VERSION ""

NS_ :

BS_:

BU_: IBST ESP EPAS EPAS3P APS APP DAS

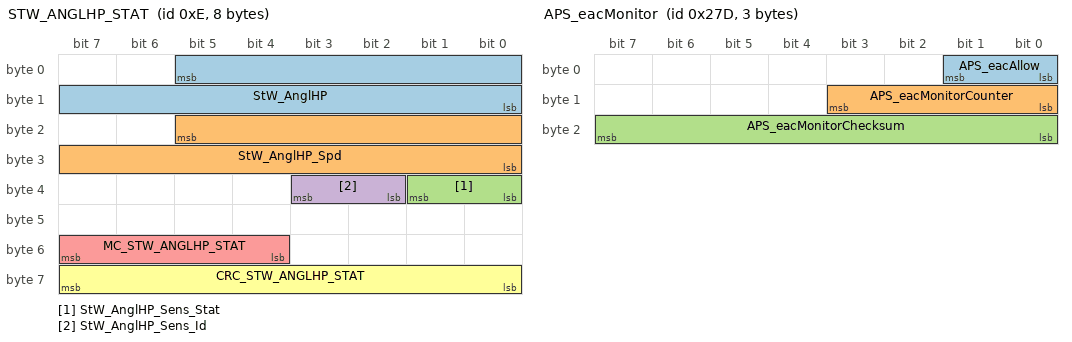
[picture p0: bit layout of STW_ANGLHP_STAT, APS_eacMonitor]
BO_ 14 STW_ANGLHP_STAT: 8 APS
  SG_ StW_AnglHP : 5|14@0+ (0.1,-819.2) [-819.2|819] "deg" EPAS3P
  SG_ StW_AnglHP_Spd : 21|14@0+ (0.5,-4096) [-4096|4095.5] "deg/s" EPAS3P
  SG_ StW_AnglHP_Sens_Stat : 33|2@0+ (1,0) [0|0] "" EPAS3P
  SG_ StW_AnglHP_Sens_Id : 35|2@0+ (1,0) [0|0] "" EPAS3P
  SG_ MC_STW_ANGLHP_STAT : 55|4@0+ (1,0) [0|15] "" EPAS3P
  SG_ CRC_STW_ANGLHP_STAT : 63|8@0+ (1,0) [0|0] "" EPAS3P

BO_ 637 APS_eacMonitor: 3 APS
  SG_ APS_eacAllow : 0|2@1+ (1,0) [0|0] "" EPAS3P
  SG_ APS_eacMonitorCounter : 8|4@1+ (1,0) [0|0] "" EPAS3P
  SG_ APS_eacMonitorChecksum : 16|8@1+ (1,0) [0|0] "" EPAS3P

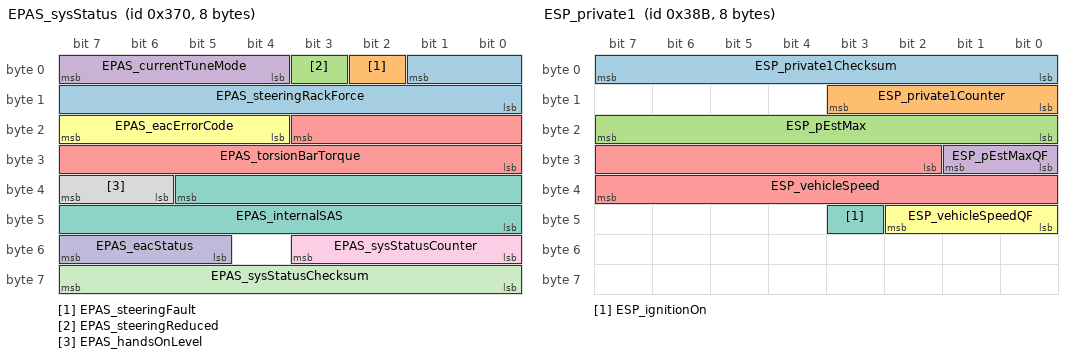
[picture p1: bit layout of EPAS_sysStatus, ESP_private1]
BO_ 880 EPAS_sysStatus: 8 EPAS
  SG_ EPAS_steeringRackForce : 1|10@0+ (50,-25575) [-25575|25575] "N" Vector__XXX
  SG_ EPAS_steeringFault : 2|1@0+ (1,0) [0|1] "" APS,APP
  SG_ EPAS_steeringReduced : 3|1@0+ (1,0) [0|1] "" APS,APP
  SG_ EPAS_currentTuneMode : 7|4@0+ (1,0) [0|0] "" APS,APP
  SG_ EPAS_torsionBarTorque : 19|12@0+ (0.01,-20.5) [-20.5|20.45] "Nm" APS,APP
  SG_ EPAS_eacErrorCode : 23|4@0+ (1,0) [0|15] "" APS,APP
  SG_ EPAS_internalSAS : 37|14@0+ (0.1,-819.2) [-819.2|819] "deg" APS,APP
  SG_ EPAS_handsOnLevel : 39|2@0+ (1,0) [0|3] "" APS,APP
  SG_ EPAS_sysStatusCounter : 51|4@0+ (1,0) [0|15] "" APS,APP
  SG_ EPAS_eacStatus : 55|3@0+ (1,0) [0|7] "" APS,APP
  SG_ EPAS_sysStatusChecksum : 63|8@0+ (1,0) [0|255] "" APS,APP

BO_ 907 ESP_private1: 8 ESP
  SG_ ESP_private1Checksum : 0|8@1+ (1,0) [0|255] "" IBST,EPAS
  SG_ ESP_private1Counter : 8|4@1+ (1,0) [0|15] "" IBST,EPAS
  SG_ ESP_pEstMax : 16|8@1+ (1,0) [0|250] "bar" IBST
  SG_ ESP_pEstMaxQF : 24|2@1+ (1,0) [0|2] "" IBST
  SG_ ESP_vehicleSpeed : 26|14@1+ (0.05625,0) [0|921.54375] "km/h" IBST,EPAS
  SG_ ESP_vehicleSpeedQF : 40|3@1+ (1,0) [0|6] "" IBST,EPAS
  SG_ ESP_ignitionOn : 43|1@1+ (1,0) [0|1] "" IBST

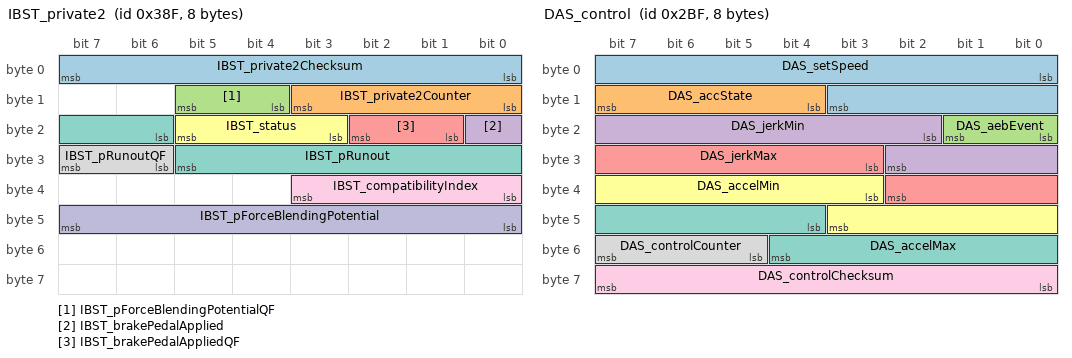
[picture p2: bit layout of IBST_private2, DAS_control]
BO_ 911 IBST_private2: 8 IBST
  SG_ IBST_private2Checksum : 0|8@1+ (1,0) [0|255] "" ESP
  SG_ IBST_private2Counter : 8|4@1+ (1,0) [0|15] "" ESP
  SG_ IBST_pForceBlendingPotentialQF : 12|2@1+ (1,0) [0|2] "" ESP
  SG_ IBST_brakePedalApplied : 16|1@1+ (1,0) [0|1] "1" ESP
  SG_ IBST_brakePedalAppliedQF : 17|2@1+ (1,0) [0|3] "" ESP
  SG_ IBST_status : 19|3@1+ (1,0) [0|7] "1" ESP
  SG_ IBST_pRunout : 22|8@1+ (1,0) [0|250] "bar" ESP
  SG_ IBST_pRunoutQF : 30|2@1+ (1,0) [0|3] "" ESP
  SG_ IBST_compatibilityIndex : 32|4@1+ (1,0) [0|15] "" ESP
  SG_ IBST_pForceBlendingPotential : 40|8@1+ (0.5,0) [0|125] "bar" ESP

BO_ 703 DAS_control: 8 DAS
  SG_ DAS_setSpeed : 0|12@1+ (0.1,0) [0|409.4] "kph" DI,PM,APS
  SG_ DAS_accState : 12|4@1+ (1,0) [0|0] "" DI,PM,APS
  SG_ DAS_aebEvent : 16|2@1+ (1,0) [0|3] "" DI,PM,APS
  SG_ DAS_jerkMin : 18|9@1+ (0.03,-15.232) [-15.232|0.098] "m/s^3" DI,PM,APS
  SG_ DAS_jerkMax : 27|8@1+ (0.059,0) [0|15.045] "m/s^3" DI,PM,APS
  SG_ DAS_accelMin : 35|9@1+ (0.04,-15) [-15|5.44] "m/s^2" DI,PM,APS
  SG_ DAS_accelMax : 44|9@1+ (0.04,-15) [-15|5.44] "m/s^2" DI,PM,APS
  SG_ DAS_controlCounter : 53|3@1+ (1,0) [0|0] "" DI,PM,APS
  SG_ DAS_controlChecksum : 56|8@1+ (1,0) [0|0] "" DI,PM,APS

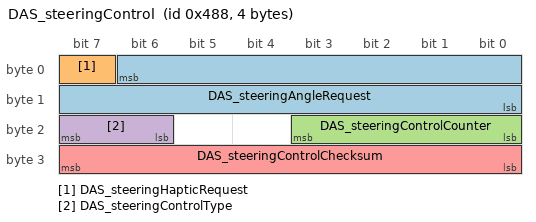
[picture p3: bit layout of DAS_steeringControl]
BO_ 1160 DAS_steeringControl: 4 DAS
  SG_ DAS_steeringAngleRequest : 6|15@0+ (0.1,-1638.35) [-1638.35|1638.35] "deg" EPAS3P,APS
  SG_ DAS_steeringHapticRequest : 7|1@0+ (1,0) [0|0] "" EPAS3P,APS
  SG_ DAS_steeringControlCounter : 19|4@0+ (1,0) [0|0] "" EPAS3P,APS
  SG_ DAS_steeringControlType : 23|2@0+ (1,0) [0|0] "" EPAS3P,APS
  SG_ DAS_steeringControlChecksum : 31|8@0+ (1,0) [0|0] "" EPAS3P,APS

VAL_ 14 StW_AnglHP 16383 "SNA" ;
VAL_ 14 StW_AnglHP_Spd 16383 "SNA" ;
VAL_ 14 StW_AnglHP_Sens_Stat 3 "SNA" 2 "ERR" 1 "INI" 0 "OK" ;
VAL_ 14 StW_AnglHP_Sens_Id 3 "SNA" 2 "KOSTAL" 1 "DELPHI" 0 "TEST" ;
VAL_ 637 APS_eacAllow 3 "APS_EAC_SNA" 2 "APS_EAC_RESERVED" 1 "APS_EAC_ALLOW" 0 "APS_EAC_INHIBIT" ;
VAL_ 880 EPAS_steeringRackForce 1023 "SNA" 1022 "NOT_IN_SPEC" ;
VAL_ 880 EPAS_steeringFault 1 "FAULT" 0 "NO_FAULT" ;
VAL_ 880 EPAS_steeringReduced 1 "REDUCED_ASSIST" 0 "NORMAL_ASSIST" ;
VAL_ 880 EPAS_currentTuneMode 7 "UNAVAILABLE" 6 "RWD_SPORT" 5 "RWD_STANDARD" 4 "RWD_COMFORT" 3 "DM_SPORT" 2 "DM_STANDARD" 1 "DM_COMFORT" 0 "FAIL_SAFE_DEFAULT" ;
VAL_ 880 EPAS_torsionBarTorque 4095 "SNA" 4094 "UNDEFINABLE_DATA" ;
VAL_ 880 EPAS_eacErrorCode 15 "SNA" 14 "EAC_EXTERNAL_MONITOR_INHIBIT" 13 "EAC_ERROR_PINION_VEL_DIFF" 12 "EAC_ERROR_LOW_ASSIST" 11 "EAC_ERROR_HIGH_TORSION_SAFETY" 10 "EAC_ERROR_HIGH_MMOT_SAFETY" 9 "EAC_ERROR_HIGH_ANGLE_RATE_SAFETY" 8 "EAC_ERROR_HIGH_ANGLE_SAFETY" 7 "EAC_ERROR_HIGH_ANGLE_RATE_REQ" 6 "EAC_ERROR_HIGH_ANGLE_REQ" 5 "EAR_ERROR_MAX_STEER_DELTA" 4 "EAC_ERROR_TMP_FAULT" 3 "EAC_ERROR_HANDS_ON" 2 "EAC_ERROR_MAX_SPEED" 1 "EAC_ERROR_MIN_SPEED" 0 "EAC_ERROR_IDLE" ;
VAL_ 880 EPAS_handsOnLevel 3 "LEVEL_3" 2 "LEVEL_2" 1 "LEVEL_1" 0 "LEVEL_0" ;
VAL_ 880 EPAS_eacStatus 7 "EAC_ELK_ACTIVE" 6 "EAC_ELK_AVAILABLE" 5 "EAC_LKA_ACTIVE" 4 "EAC_LKA_ELK_AVAILABLE" 3 "EAC_FAULT" 2 "EAC_ACTIVE" 1 "EAC_AVAILABLE" 0 "EAC_INHIBITED" ;
VAL_ 907 ESP_pEstMaxQF 2 "PESTMAX_FAULT" 1 "PESTMAX_NORMAL" 0 "PESTMAX_NOT_INITIALIZED" ;
VAL_ 907 ESP_vehicleSpeedQF 6 "SPEED_INV_UNDER_V" 5 "SPEED_NOT_CALC" 4 "SPEED_REDUCED_MON" 3 "SPEED_DIFF_CALC" 2 "SPEED_FAULT" 1 "SPEED_NORMAL" 0 "SPEED_NOT_INITIALIZED" ;
VAL_ 907 ESP_ignitionOn 1 "ESP_IGNITION_ON" 0 "ESP_IGNITION_OFF" ;
VAL_ 911 IBST_pForceBlendingPotentialQF 2 "BLENDING_POTENTIAL_FAULT" 1 "BLENDING_POTENTIAL_NORMAL" 0 "BLENDING_POTENTIAL_NOT_INIT" ;
VAL_ 911 IBST_brakePedalApplied 1 "BRAKE_PEDAL_APPLIED" 0 "BRAKE_PEDAL_NOT_APPLIED" ;
VAL_ 911 IBST_brakePedalAppliedQF 2 "BRAKE_PEDAL_APPLIED_FAULT" 1 "BRAKE_PEDAL_APPLIED_NORMAL" 0 "BRAKE_PEDAL_APPLIED_OFF" ;
VAL_ 911 IBST_status 7 "IBOOSTER_READY" 6 "IBOOSTER_POST_RUN_REDUCED" 5 "IBOOSTER_REDUCED" 4 "IBOOSTER_STANDALONE" 3 "IBOOSTER_UNDEFINED_1" 2 "IBOOSTER_DIAGNOSTIC" 1 "IBOOSTER_FAULT" 0 "IBOOSTER_NOT_INITIALIZED" ;
VAL_ 911 IBST_pRunoutQF 2 "RUNNOUT_FAULT" 1 "RUNNOUT_NORMAL" 0 "RUNNOUT_NOT_INITIALIZED" ;
VAL_ 703 DAS_setSpeed 4095 "SNA" ;
VAL_ 703 DAS_accState 15 "FAULT_SNA" 13 "ACC_CANCEL_GENERIC_SILENT" 11 "APC_SELFPARK_START" 10 "APC_UNPARK_COMPLETE" 9 "APC_PAUSE" 8 "APC_ABORT" 7 "APC_COMPLETE" 6 "APC_FORWARD" 5 "APC_BACKWARD" 4 "ACC_ON" 3 "ACC_HOLD" 0 "ACC_CANCEL_GENERIC" ;
VAL_ 703 DAS_aebEvent 3 "AEB_SNA" 2 "AEB_FAULT" 1 "AEB_ACTIVE" 0 "AEB_NOT_ACTIVE" ;
VAL_ 703 DAS_jerkMin 511 "SNA" ;
VAL_ 703 DAS_jerkMax 255 "SNA" ;
VAL_ 703 DAS_accelMin 511 "SNA" ;
VAL_ 703 DAS_accelMax 511 "SNA" ;
VAL_ 1160 DAS_steeringAngleRequest 16384 "ZERO_ANGLE" ;
VAL_ 1160 DAS_steeringHapticRequest 1 "HAPTIC_ACTIVE" 0 "HAPTIC_IDLE" ;
VAL_ 1160 DAS_steeringControlType 3 "EMERGENCY_LANE_KEEP" 2 "LANE_KEEP_ASSIST" 1 "ANGLE_CONTROL" 0 "NONE" ;
